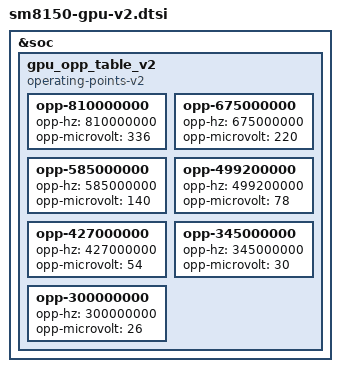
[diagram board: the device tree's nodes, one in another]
/* Copyright (c) 2018-2019, The Linux Foundation. All rights reserved.
 *
 * This program is free software; you can redistribute it and/or modify
 * it under the terms of the GNU General Public License version 2 and
 * only version 2 as published by the Free Software Foundation.
 *
 * This program is distributed in the hope that it will be useful,
 * but WITHOUT ANY WARRANTY; without even the implied warranty of
 * MERCHANTABILITY or FITNESS FOR A PARTICULAR PURPOSE.  See the
 * GNU General Public License for more details.
 */

&soc {
	gpu_opp_table_v2: gpu_opp_table_v2 {
		compatible = "operating-points-v2";

		opp-810000000 {
			opp-hz = /bits/ 64 <810000000>;
			opp-microvolt = <336>;
		};

		opp-675000000 {
			opp-hz = /bits/ 64 <675000000>;
			opp-microvolt = <220>;
		};

		opp-585000000 {
			opp-hz = /bits/ 64 <585000000>;
			opp-microvolt = <140>;
		};

		opp-499200000 {
			opp-hz = /bits/ 64 <499200000>;
			opp-microvolt = <78>;
		};

		opp-427000000 {
			opp-hz = /bits/ 64 <427000000>;
			opp-microvolt = <54>;
		};

		opp-345000000 {
			opp-hz = /bits/ 64 <345000000>;
			opp-microvolt = <30>;
		};

		opp-300000000 {
			opp-hz = /bits/ 64 <300000000>;
			opp-microvolt = <26>;
		};
	};
};
